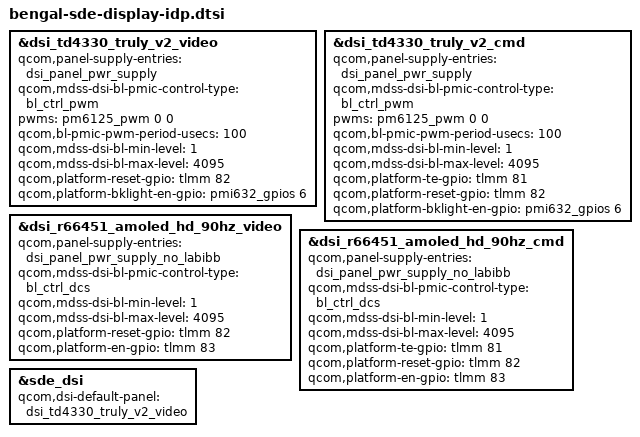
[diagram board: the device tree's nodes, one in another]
#include "bengal-sde-display.dtsi"

&dsi_td4330_truly_v2_video {
	qcom,panel-supply-entries = <&dsi_panel_pwr_supply>;
	qcom,mdss-dsi-bl-pmic-control-type = "bl_ctrl_pwm";
	pwms = <&pm6125_pwm 0 0>;
	qcom,bl-pmic-pwm-period-usecs = <100>;
	qcom,mdss-dsi-bl-min-level = <1>;
	qcom,mdss-dsi-bl-max-level = <4095>;
	qcom,platform-reset-gpio = <&tlmm 82 0>;
	qcom,platform-bklight-en-gpio = <&pmi632_gpios 6 0>;
};

&dsi_td4330_truly_v2_cmd {
	qcom,panel-supply-entries = <&dsi_panel_pwr_supply>;
	qcom,mdss-dsi-bl-pmic-control-type = "bl_ctrl_pwm";
	pwms = <&pm6125_pwm 0 0>;
	qcom,bl-pmic-pwm-period-usecs = <100>;
	qcom,mdss-dsi-bl-min-level = <1>;
	qcom,mdss-dsi-bl-max-level = <4095>;
	qcom,platform-te-gpio = <&tlmm 81 0>;
	qcom,platform-reset-gpio = <&tlmm 82 0>;
	qcom,platform-bklight-en-gpio = <&pmi632_gpios 6 0>;
};

&dsi_r66451_amoled_hd_90hz_video {
	qcom,panel-supply-entries = <&dsi_panel_pwr_supply_no_labibb>;
	qcom,mdss-dsi-bl-pmic-control-type = "bl_ctrl_dcs";
	qcom,mdss-dsi-bl-min-level = <1>;
	qcom,mdss-dsi-bl-max-level = <4095>;
	qcom,platform-reset-gpio = <&tlmm 82 0>;
	qcom,platform-en-gpio = <&tlmm 83 0>;
};

&dsi_r66451_amoled_hd_90hz_cmd {
	qcom,panel-supply-entries = <&dsi_panel_pwr_supply_no_labibb>;
	qcom,mdss-dsi-bl-pmic-control-type = "bl_ctrl_dcs";
	qcom,mdss-dsi-bl-min-level = <1>;
	qcom,mdss-dsi-bl-max-level = <4095>;
	qcom,platform-te-gpio = <&tlmm 81 0>;
	qcom,platform-reset-gpio = <&tlmm 82 0>;
	qcom,platform-en-gpio = <&tlmm 83 0>;
};

&sde_dsi {
	qcom,dsi-default-panel = <&dsi_td4330_truly_v2_video>;
};
/*
&qupv3_se2_i2c {
	status = "okay";
	qcom,i2c-touch-active="synaptics,tcm-i2c";

	synaptics_tcm@20 {
		compatible = "synaptics,tcm-i2c";
		reg = <0x20>;
		interrupt-parent = <&tlmm>;
		interrupts = <80 0x2008>;
		pinctrl-names = "pmx_ts_active","pmx_ts_suspend",
			"pmx_ts_release";
		pinctrl-0 = <&ts_int_active &ts_reset_active>;
		pinctrl-1 = <&ts_int_suspend &ts_reset_suspend>;
		pinctrl-2 = <&ts_release>;
		synaptics,irq-gpio = <&tlmm 80 0x2008>;
		synaptics,irq-on-state = <0>;
		synaptics,reset-gpio = <&tlmm 71 0x00>;
		synaptics,reset-on-state = <0>;
		synaptics,reset-active-ms = <20>;
		synaptics,reset-delay-ms = <200>;
		synaptics,power-delay-ms = <200>;
		synaptics,ubl-i2c-addr = <0x20>;
		synaptics,extend_report;
		synaptics,firmware-name = "synaptics_firmware_k.img";

		panel = <&dsi_td4330_truly_v2_video &dsi_td4330_truly_v2_cmd>;
	};

	focaltech@38 {
		compatible = "focaltech,fts_ts";
		reg = <0x38>;
		interrupt-parent = <&tlmm>;
		interrupts = <80 0x2008>;
		focaltech,reset-gpio = <&tlmm 71 0x00>;
		focaltech,irq-gpio = <&tlmm 80 0x2008>;
		focaltech,max-touch-number = <5>;
		focaltech,display-coords = <0 0 1080 2340>;

		vdd-supply = <&touch_vdd>;

		pinctrl-names = "pmx_ts_active","pmx_ts_suspend",
				"pmx_ts_release";
		pinctrl-0 = <&ts_int_active &ts_reset_active>;
		pinctrl-1 = <&ts_int_suspend &ts_reset_suspend>;
		pinctrl-2 = <&ts_release>;

		panel = <&dsi_r66451_amoled_hd_90hz_video
			&dsi_r66451_amoled_hd_90hz_cmd>;
	};

};
*/
